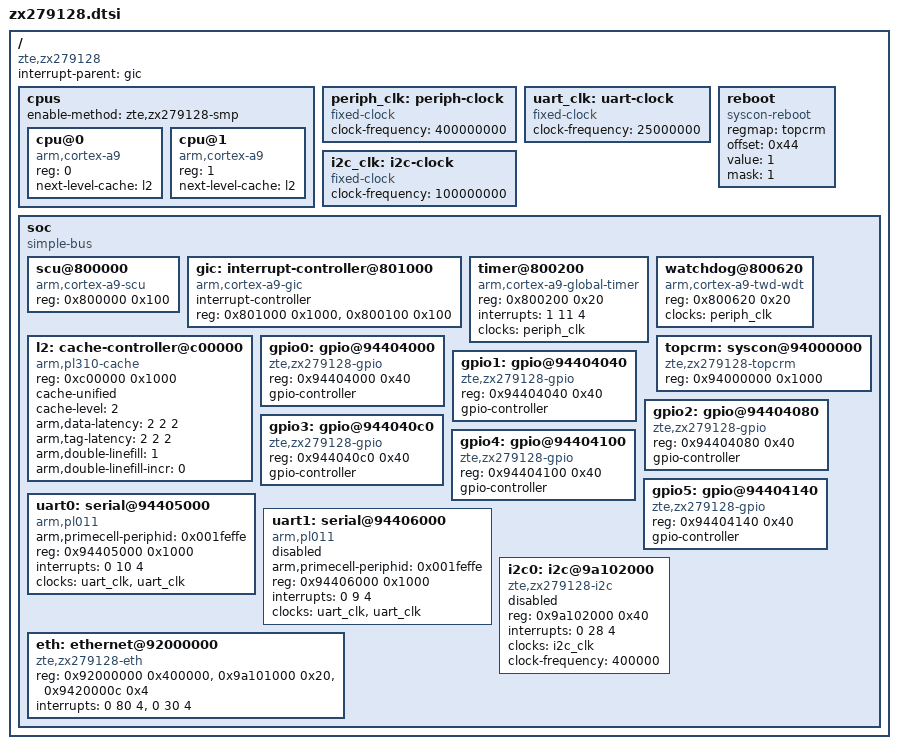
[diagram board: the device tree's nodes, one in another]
// SPDX-License-Identifier: GPL-2.0-or-later OR MIT
/*
 * ZTE ZX279128: dual Cortex-A9 MPCore (private peripherals at 0x800000), PL310 L2 at 0xc00000. Addresses and
 * interrupts as the unit's own stock device tree and console show them.
 */
/* GIC cells written as numbers (0 = SPI, 1 = PPI; 4 = level high) so the tree compiles without kernel headers. */

/ {
	#address-cells = <1>;
	#size-cells = <1>;
	compatible = "zte,zx279128";
	interrupt-parent = <&gic>;

	cpus {
		#address-cells = <1>;
		#size-cells = <0>;
		enable-method = "zte,zx279128-smp";

		cpu@0 {
			device_type = "cpu";
			compatible = "arm,cortex-a9";
			reg = <0>;
			next-level-cache = <&l2>;
		};

		cpu@1 {
			device_type = "cpu";
			compatible = "arm,cortex-a9";
			reg = <1>;
			next-level-cache = <&l2>;
		};
	};

	/* PERIPHCLK: the stock sched_clock and watchdog both run "at 400MHz". */
	periph_clk: periph-clock {
		compatible = "fixed-clock";
		#clock-cells = <0>;
		clock-frequency = <400000000>;
	};

	/* U-Boot's 115200 divisor (IBRD 13, FBRD 36) puts the UART reference at 25 MHz. */
	uart_clk: uart-clock {
		compatible = "fixed-clock";
		#clock-cells = <0>;
		clock-frequency = <25000000>;
	};

	/* I2C0's input clock: the stock divider 249 makes its 400 kHz. */
	i2c_clk: i2c-clock {
		compatible = "fixed-clock";
		#clock-cells = <0>;
		clock-frequency = <100000000>;
	};

	/* topcrm 0x44 bit 0 resets the whole SoC, as the stock kernel's restart does. */
	reboot {
		compatible = "syscon-reboot";
		regmap = <&topcrm>;
		offset = <0x44>;
		value = <1>;
		mask = <1>;
	};

	soc {
		compatible = "simple-bus";
		#address-cells = <1>;
		#size-cells = <1>;
		ranges;

		scu@800000 {
			compatible = "arm,cortex-a9-scu";
			reg = <0x800000 0x100>;
		};

		gic: interrupt-controller@801000 {
			compatible = "arm,cortex-a9-gic";
			#interrupt-cells = <3>;
			interrupt-controller;
			reg = <0x801000 0x1000>, <0x800100 0x100>;
		};

		timer@800200 {
			compatible = "arm,cortex-a9-global-timer";
			reg = <0x800200 0x20>;
			interrupts = <1 11 4>;
			clocks = <&periph_clk>;
		};

		/* CPU0's private watchdog, in watchdog mode (the stock tree's own node). */
		watchdog@800620 {
			compatible = "arm,cortex-a9-twd-wdt";
			reg = <0x800620 0x20>;
			clocks = <&periph_clk>;
		};

		l2: cache-controller@c00000 {
			compatible = "arm,pl310-cache";
			reg = <0xc00000 0x1000>;
			cache-unified;
			cache-level = <2>;
			arm,data-latency = <2 2 2>;
			arm,tag-latency = <2 2 2>;
			arm,double-linefill = <1>;
			arm,double-linefill-incr = <0>;
		};

		topcrm: syscon@94000000 {
			compatible = "zte,zx279128-topcrm", "syscon";
			reg = <0x94000000 0x1000>;
		};

		/* GPIO 0..95, 16 lines per bank (GPIO n = bank n / 16, line n % 16), as the stock kernel maps them. */
		gpio0: gpio@94404000 {
			compatible = "zte,zx279128-gpio";
			reg = <0x94404000 0x40>;
			gpio-controller;
			#gpio-cells = <2>;
		};

		gpio1: gpio@94404040 {
			compatible = "zte,zx279128-gpio";
			reg = <0x94404040 0x40>;
			gpio-controller;
			#gpio-cells = <2>;
		};

		gpio2: gpio@94404080 {
			compatible = "zte,zx279128-gpio";
			reg = <0x94404080 0x40>;
			gpio-controller;
			#gpio-cells = <2>;
		};

		gpio3: gpio@944040c0 {
			compatible = "zte,zx279128-gpio";
			reg = <0x944040c0 0x40>;
			gpio-controller;
			#gpio-cells = <2>;
		};

		gpio4: gpio@94404100 {
			compatible = "zte,zx279128-gpio";
			reg = <0x94404100 0x40>;
			gpio-controller;
			#gpio-cells = <2>;
		};

		gpio5: gpio@94404140 {
			compatible = "zte,zx279128-gpio";
			reg = <0x94404140 0x40>;
			gpio-controller;
			#gpio-cells = <2>;
		};

		/* A PL011 at ZTE register offsets: the periphid selects that layout in amba-pl011. */
		uart0: serial@94405000 {
			compatible = "arm,pl011", "arm,primecell";
			arm,primecell-periphid = <0x001feffe>;
			reg = <0x94405000 0x1000>;
			interrupts = <0 10 4>;
			clocks = <&uart_clk>, <&uart_clk>;
			clock-names = "uartclk", "apb_pclk";
		};

		uart1: serial@94406000 {
			compatible = "arm,pl011", "arm,primecell";
			arm,primecell-periphid = <0x001feffe>;
			reg = <0x94406000 0x1000>;
			interrupts = <0 9 4>;
			clocks = <&uart_clk>, <&uart_clk>;
			clock-names = "uartclk", "apb_pclk";
			status = "disabled";
		};

		/* Its completion raises SPI 28 (measured; the stock tree says 26, which its polling driver never uses). */
		i2c0: i2c@9a102000 {
			compatible = "zte,zx279128-i2c", "zte,zx296718-i2c";
			reg = <0x9a102000 0x40>;
			interrupts = <0 28 4>;
			clocks = <&i2c_clk>;
			clock-frequency = <400000>;
			#address-cells = <1>;
			#size-cells = <0>;
			status = "disabled";
		};

		/* The packet processor, the switch with its four port MACs and the MDIO master; receive interrupt SPI 80;
		 * the third range is the pinmux word whose bit 17 the PON start clears. */
		eth: ethernet@92000000 {
			compatible = "zte,zx279128-eth";
			reg = <0x92000000 0x400000>, <0x9a101000 0x20>, <0x9420000c 0x4>;
			interrupts = <0 80 4>, <0 30 4>;
		};
	};
};
